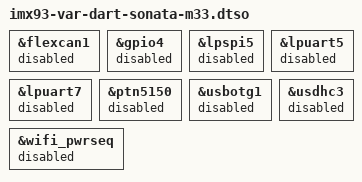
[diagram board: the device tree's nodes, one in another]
// SPDX-License-Identifier: (GPL-2.0+ OR MIT)
/*
 * Cortex-M33 support for Variscite DART-MX93 on Sonata-Board
 *
 * Link: https://variscite.com/carrier-boards/sonata-board/
 *
 * Copyright (C) 2026 Variscite Ltd. - https://www.variscite.com/
 *
 */

/dts-v1/;
/plugin/;

#include "imx93-var-common-m33.dtsi"

/* Reserve the peripherals used by the Cortex-M33 firmware. */
&flexcan1 {
	status = "reserved";
};

&gpio4 {
	status = "reserved";
};

&lpspi5 {
	status = "reserved";
};

/* Disable Bluetooth along with Wi-Fi and release the JTAG pins. */
&lpuart5 {
	status = "disabled";
};

&lpuart7 {
	status = "reserved";
};

/* The USB-C role controller uses an interrupt on GPIO4. */
&ptn5150 {
	status = "disabled";
};

/* The USB-C role controller is unavailable. */
&usbotg1 {
	status = "disabled";
};

/* Wi-Fi reset is connected to GPIO4. */
&usdhc3 {
	status = "disabled";
};

&wifi_pwrseq {
	status = "disabled";
};
